# dp_sink_model: IP-XACT component
VLNV IcronTechnologies:IcronTechnologies:dp_sink_model:1.0

## Parameters
addr_width = 9
bus_width = 32

## Bus interfaces (logical=physical port)
default_map: slave AGNISYS:AGNISYS:APB:1.0, memory map dp_sinkmap
  pclk=pclk, presetn=presetn, psel=psel, penable=penable, pwrite=pwrite, pprot=pprot, pstrb=pstrb, pwdata=pwdata, paddr=paddr, pready=pready, prdata=prdata, pslverr=pslverr

## Ports
in pclk
in presetn
in psel
in penable
in pwrite
in pprot[2:0]
in pstrb[(bus_width div 8 )-1:0]
in pwdata[bus_width -1:0]
in paddr[addr_width -1:0]
out pready
out prdata[bus_width -1:0]
out pslverr
out dp_sink_regsversion_major_r[7:0]
out dp_sink_regsversion_minor_r[7:0]
out dp_sink_regsversion_patch_r[7:0]
out dp_sink_regsconfiguration_enb
out dp_sink_regsconfiguration_debug_msa_en_r
in dp_sink_regsconfiguration_tu_measured_in
in dp_sink_regsconfiguration_tu_measured_in_enb
in dp_sink_regsconfiguration_tico_ctrl_rst_in
in dp_sink_regsconfiguration_tico_ctrl_rst_in_enb
in dp_sink_regsconfiguration_vid_color_format_in[1:0]
in dp_sink_regsconfiguration_vid_color_format_in_enb
in dp_sink_regsconfiguration_vid_bit_per_component_in[2:0]
in dp_sink_regsconfiguration_vid_bit_per_component_in_enb
out dp_sink_regsconfiguration_vid_stream_extractor_en_r
out dp_sink_regsconfiguration_stream_extractor_en_r
out dp_sink_regsconfiguration_apb_to_axi_mode_select_r
out dp_sink_regsconfiguration_enh_frm_en_r
out dp_sink_regsconfiguration_lane_bit_rate_r[1:0]
out dp_sink_regsconfiguration_lane_num_r[1:0]
out dp_sink_regsdescrambler_enb
out dp_sink_regsdescrambler_enable_r
out dp_sink_regsaligner_control_enb
out dp_sink_regsaligner_control_tps3_n_tps2_r
out dp_sink_regsaligner_control_align_en_r
out dp_sink_regsaligner_stats_enb
out dp_sink_regsaligner_stats_lanes_not_aligned_cnt_rst_r
out dp_sink_regsaligner_stats_lanes_align_det_en_r
out dp_sink_regsstats_cnt_en_rst_8b10b_0_enb
out dp_sink_regsstats_cnt_en_rst_8b10b_0_lane{n}_8b10b_dis_err_post_cr_cnt_rst_r (n=0..3)
out dp_sink_regsstats_cnt_en_rst_8b10b_0_lanes_8b10b_dis_err_det_en_r
out dp_sink_regsstats_cnt_en_rst_8b10b_1_enb
out dp_sink_regsstats_cnt_en_rst_8b10b_1_lane{n}_8b10b_nit_err_post_cr_cnt_rst_r (n=0..3)
out dp_sink_regsstats_cnt_en_rst_8b10b_1_lanes_8b10b_nit_err_det_en_r
out dp_sink_regsstats_cnt_en_rst_gtp_enb
out dp_sink_regsstats_cnt_en_rst_gtp_dp_gt_rxbyterealign_cnt_rst_r
out dp_sink_regsstats_cnt_en_rst_gtp_dp_gt_rxbyterealign_cnt_en_r
out dp_sink_regsstream_extractor_cfg_enb
out dp_sink_regsstream_extractor_cfg_sdp_en_r
out dp_sink_regsstream_extractor_cfg_drop_sdp_ptp_pkt_r
out dp_sink_regsstream_extractor_cfg_drop_cs_ptp_pkt_r
out dp_sink_regsstream_extractor_cfg_cs_pkt_length_r[11:0]
out dp_sink_regsstream_extractor_alu_enb
out dp_sink_regsstream_extractor_alu_encoder_program_done_r
out dp_sink_regsstream_extractor_pixgen_enb
out dp_sink_regsstream_extractor_pixgen_en_r
out dp_sink_regsstream_extractor_pixgen_blue_r[7:0]
out dp_sink_regsstream_extractor_pixgen_green_r[7:0]
out dp_sink_regsstream_extractor_pixgen_red_r[7:0]
out dp_sink_regsstream_extractor_debug_enb
out dp_sink_regsstream_extractor_debug_idle_pattern_cnt_rst_r
out dp_sink_regsstream_extractor_msa_fps_enb
out dp_sink_regsstream_extractor_msa_fps_count_en_r
out dp_sink_regsstream_extractor_debug_msa_mvid_enb
out dp_sink_regsstream_extractor_debug_msa_mvid_mvid_r[23:0]
out dp_sink_regsstream_extractor_debug_msa_nvid_enb
out dp_sink_regsstream_extractor_debug_msa_nvid_nvid_r[23:0]
out dp_sink_regsstream_extractor_debug_msa_horizontal_0_enb
out dp_sink_regsstream_extractor_debug_msa_horizontal_0_total_r[15:0]
out dp_sink_regsstream_extractor_debug_msa_horizontal_0_start_r[15:0]
out dp_sink_regsstream_extractor_debug_msa_horizontal_1_enb
out dp_sink_regsstream_extractor_debug_msa_horizontal_1_width_r[15:0]
out dp_sink_regsstream_extractor_debug_msa_horizontal_1_polarity_r
out dp_sink_regsstream_extractor_debug_msa_horizontal_1_sync_width_r[14:0]
out dp_sink_regsstream_extractor_debug_msa_vertical_0_enb
out dp_sink_regsstream_extractor_debug_msa_vertical_0_total_r[15:0]
out dp_sink_regsstream_extractor_debug_msa_vertical_0_start_r[15:0]
out dp_sink_regsstream_extractor_debug_msa_vertical_1_enb
out dp_sink_regsstream_extractor_debug_msa_vertical_1_height_r[15:0]
out dp_sink_regsstream_extractor_debug_msa_vertical_1_polarity_r
out dp_sink_regsstream_extractor_debug_msa_vertical_1_sync_width_r[14:0]
out dp_sink_regsstream_extractor_debug_msa_misc_enb
out dp_sink_regsstream_extractor_debug_msa_misc_y_only_r
out dp_sink_regsstream_extractor_debug_msa_misc_stereo_r[1:0]
out dp_sink_regsstream_extractor_debug_msa_misc_int_total_r
out dp_sink_regsstream_extractor_debug_msa_misc_color_r[6:0]
out dp_sink_regsstream_extractor_debug_msa_misc_clk_sync_r
out dp_sink_regsstats0_rd2clr_config_rd_valid_out
out dp_sink_regsstats0_rd2clr_config_wr_valid_out
out dp_sink_regsstats0_vid_c{n}_fifo_full_rd_valid_out (n=0..2)
out dp_sink_regsstats0_vid_c{n}_fifo_empty_rd_valid_out (n=0..2)
out dp_sink_regsstats0_vid_c{n}_fifo_overflow_rd_valid_out (n=0..2)
out dp_sink_regsstats0_vid_c{n}_fifo_underflow_rd_valid_out (n=0..2)
out dp_sink_regsstats0_vid_c{n}_fifo_level_rd_valid_out (n=0..2)
out dp_sink_regsstats0_vid_c{n}_fifo_level_watermark_rd_valid_out (n=0..2)
out dp_sink_regsstats0_vid_c{n}_sr_full_rd_valid_out (n=0..2)
out dp_sink_regsstats0_vbd_majority_fail_rd_valid_out
out dp_sink_regsstats0_msa_majority_fail_rd_valid_out
out dp_sink_regsstats1_rd2clr_config_rd_valid_out
out dp_sink_regsstats1_rd2clr_config_wr_valid_out
out dp_sink_regsstats1_sdp_pkt_sent_cnt_rd_valid_out
out dp_sink_regsstats1_sdp_pkt_sent_cnt_watermark_rd_valid_out
out dp_sink_regsstats1_sdp_ss_se_same_cycle_rd_valid_out
out dp_sink_regsstats1_sdp_fifo_full_rd_valid_out
out dp_sink_regsstats1_sdp_fifo_empty_rd_valid_out
out dp_sink_regsstats1_sdp_fifo_overflow_rd_valid_out
out dp_sink_regsstats1_sdp_fifo_underflow_rd_valid_out
out dp_sink_regsstats1_sdp_fifo_level_rd_valid_out
out dp_sink_regsstats1_sdp_fifo_level_watermark_rd_valid_out
out dp_sink_regsstats1_sdp_tag_fifo_full_rd_valid_out
out dp_sink_regsstats1_sdp_tag_fifo_empty_rd_valid_out
out dp_sink_regsstats1_sdp_tag_fifo_overflow_rd_valid_out
out dp_sink_regsstats1_sdp_tag_fifo_underflow_rd_valid_out
out dp_sink_regsstats1_sdp_tag_fifo_level_rd_valid_out
out dp_sink_regsstats1_sdp_tag_fifo_level_watermark_rd_valid_out

## Address spaces and blocks
dp_sinkmap.dp_sink: base 0x000, range 0x200, width 32

## Registers
Registers are 32-bit, read-only, reset 0x0 unless marked. A register's access mark holds for its fields unless they carry their own. Offsets are from the block's base; lines under a group give offsets from that group; [hi:lo] are bit positions; {n}, {i} and the like mark numbered series; 'fields as' and 'values as' point back to an identical list; <NAME> marks a mode.

## dp_sinkmap.dp_sink — DP Sink
Base 0x00000000
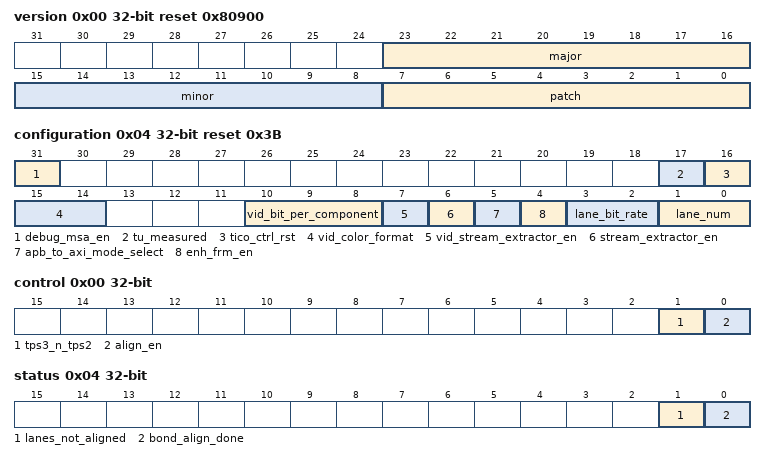
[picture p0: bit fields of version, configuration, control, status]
0x00 version reset 0x80900
  [23:16] major — Major version
  [15:8] minor — Minor version
  [7:0] patch — Patch version
0x04 configuration access per field reset 0x3B — General configuration
  [31] debug_msa_en rw — Enable debug MSA registers
  [17] tu_measured ro — tu_measured signal status
  [16] tico_ctrl_rst ro — Tico Encoder ctrl_rst pin status
  [15:14] vid_color_format ro — DP video color format 2'b00: RGB888 2'b01: YCbCr444 2'b10: YCbCr422 2'b11: YCbCr420
  [10:8] vid_bit_per_component ro — DP video bits per component 3'b000: 6 3'b001: 8 3'b010: 10 3'b011: 12 3'b100: 16
  [7] vid_stream_extractor_en rw — Enable video related stream_extractor module
  [6] stream_extractor_en rw — Enable stream_extractor module
  [5] apb_to_axi_mode_select rw — APB to AXI read mode select 1'b1: The read cycle is at least one clock later than read address cycle 1'b0: The read cycle happens at the same cycle as read address cycle
  [4] enh_frm_en rw — DP enhanced framing mode enable. The enhanced mode is enabled when this bit is set to 1.
  [3:2] lane_bit_rate rw — DP serial bit rate 2'b00: RBR (1.62 Gbps) 2'b01: HBR (2.70 Gbps) 2'b10: HBR2 (5.40 Gbps) 2'b11: HBR3(8.10 Gbps)
  [1:0] lane_num rw — Number of active dp lanes 2'b00: 1 lane 2'b01: 2 lanes 2'b10: Invalid 2'b11: 4 lanes
0x08 aligner group — Aligner module registers
  0x00 control rw — Aligner module control register
    [1] tps3_n_tps2 — Test pattern selection 1'b0: TPS2 1'b1: TPS3
    [0] align_en — Align module enable 1'b0: Disable 1'b1: Enable
  0x04 status — Aligner module bond/align status register
    [1] lanes_not_aligned — Alignment is not correct even though bond_align_done is set to high
    [0] bond_align_done — Alignment and bonding status. A "1" indicates all active lanes are bonded and aligned
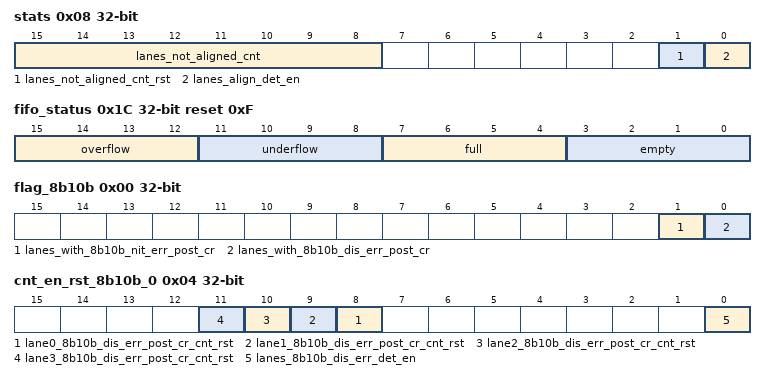
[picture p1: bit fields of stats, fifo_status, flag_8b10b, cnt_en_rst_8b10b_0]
  0x08 stats access per field — Aligner lanes not aligned
    [15:8] lanes_not_aligned_cnt ro — Number of clock cycles where lanes are not aligned after detection is enabled
    [1] lanes_not_aligned_cnt_rst rw — Align detector logic enable 1'b0: Disable 1'b1: Enable
    [0] lanes_align_det_en rw — Align detector logic enable 1'b0: Disable 1'b1: Enable
  0x0C debug group — Aligner debug stats
    0x00 stats1 — Aligner FSM
      [31:0] state_dbg
    0x04 stats2 — Aligner FIFO read enables
      [31:0] fifo_rd_en_dbg
    0x08 stats3 — Aligner comma detect
      [31:0] com_det_dbg
    0x0C stats4 — Aligner debug data
      [23:0] bond_align_debug_stats — Several stats for debugging
  0x1C fifo_status reset 0xF — Aligner module FIFO status register
    [15:12] overflow — FIFO overflow status. A "1" indicates overflow in FIFO. Bit[12] corresponds to lane 0 FIFO Bit[13] corresponds to lane 1 FIFO Bit[14] corresponds to lane 2 FIFO Bit[15] corresponds to lane 3 FIFO
    [11:8] underflow — FIFO underflow status. A "1" indicates underflow in FIFO. Bit[8] corresponds to lane 0 FIFO Bit[9] corresponds to lane 1 FIFO Bit[10] corresponds to lane 2 FIFO Bit[11] corresponds to lane 3 FIFO
    [7:4] full — FIFO full status. A "1" indicates FIFO is full Bit[4] corresponds to lane 0 FIFO Bit[5] corresponds to lane 1 FIFO Bit[6] corresponds to lane 2 FIFO Bit[7] corresponds to lane 3 FIFO
    [3:0] empty — FIFO empty status. A "1" indicates FIFO is empty Bit[0] corresponds to lane 0 FIFO Bit[1] corresponds to lane 1 FIFO Bit[2] corresponds to lane 2 FIFO Bit[3] corresponds to lane 3 FIFO
  0x20 fifo_config — Aligner depth
    [7:0] depth — FIFO depth. This value is used for the build
0x2C stats group — 8b10b and gtp debug stats
  0x00 flag_8b10b — 8b10b error flag
    [1] lanes_with_8b10b_nit_err_post_cr — There are 8b10b not in table decoder errors
    [0] lanes_with_8b10b_dis_err_post_cr — There are 8b10b disparity decoder errors
  0x04 cnt_en_rst_8b10b_0 rw — 8b10b disparity error counts reset
    [n+8] lane{n}_8b10b_dis_err_post_cr_cnt_rst (n=0..3) — 8b10b disparity error reset on lane {n}
    [0] lanes_8b10b_dis_err_det_en — 8b10b disparity error detector enable
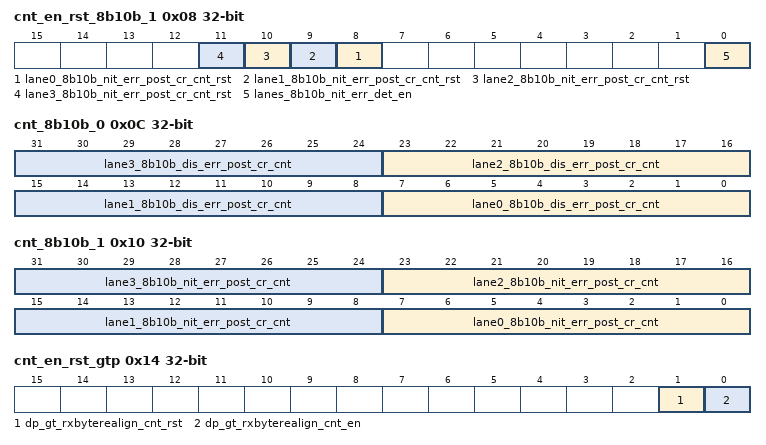
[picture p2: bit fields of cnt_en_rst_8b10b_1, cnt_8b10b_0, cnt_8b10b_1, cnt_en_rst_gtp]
  0x08 cnt_en_rst_8b10b_1 rw — 8b10b not in table error counts reset
    [n+8] lane{n}_8b10b_nit_err_post_cr_cnt_rst (n=0..3) — 8b10b not in table error reset on lane {n}
    [0] lanes_8b10b_nit_err_det_en — 8b10b not in table error detector enable
  0x0C cnt_8b10b_0 — 8b10b disparity error counts
    [8n+7:8n] lane{n}_8b10b_dis_err_post_cr_cnt (n=0..3) — Number of 8b10b disparity errors on lane {n}
  0x10 cnt_8b10b_1 — 8b10b not in table error counts
    [8n+7:8n] lane{n}_8b10b_nit_err_post_cr_cnt (n=0..3) — Number of 8b10b not in table errors on lane {n}
  0x14 cnt_en_rst_gtp rw — GTP realign counts
    [1] dp_gt_rxbyterealign_cnt_rst — Reset the rxbytealign counters
    [0] dp_gt_rxbyterealign_cnt_en — Enable the rxbyterealign counters
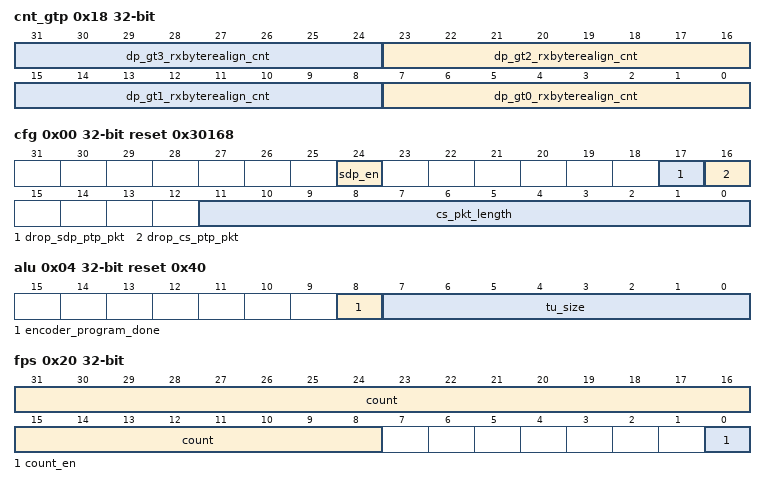
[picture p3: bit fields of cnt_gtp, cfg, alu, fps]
  0x18 cnt_gtp — GTP realign counts
    [8n+7:8n] dp_gt{n}_rxbyterealign_cnt (n=0..3) — Number of clock cycles where gt{n} symbol is realigned
0x48 descrambler rw
  [0] enable — Descrambler enable bit. The descrambler is enabled when this bit is set to 1. It is bypassed when this bit is set to 0.
0x4C stream_extractor group
  0x00 cfg rw reset 0x30168
    [24] sdp_en — Enable SDP
    [17] drop_sdp_ptp_pkt — Drop SDP packets going to MCA
    [16] drop_cs_ptp_pkt — Drop CS packets going to MCA
    [11:0] cs_pkt_length — Compressed video packet length
  0x04 alu access per field reset 0x40
    [8] encoder_program_done rw — Encoder programming is completed
    [7:0] tu_size ro — TU size receved from host
  0x08 msa group
    0x00 mvid
      [23:0] mvid — msa mvid value
    0x04 nvid
      [23:0] nvid — msa nvid value
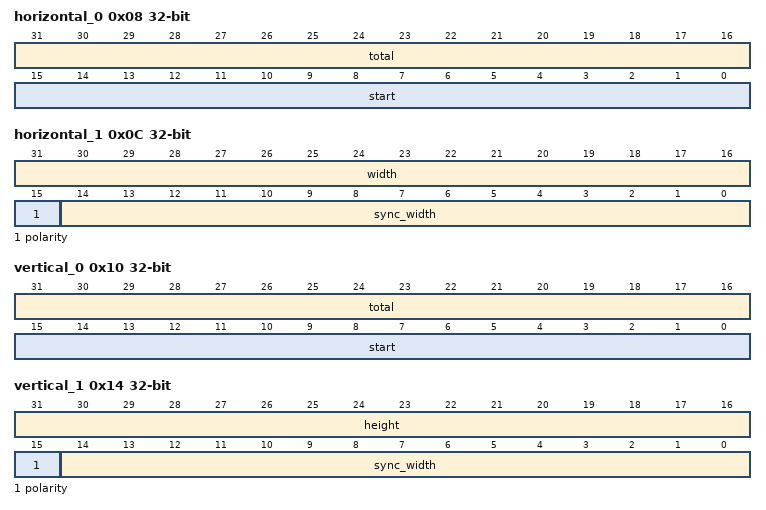
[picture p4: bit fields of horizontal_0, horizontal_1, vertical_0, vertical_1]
    0x08 horizontal_0
      [31:16] total — msa h total
      [15:0] start — msa h start
    0x0C horizontal_1
      [31:16] width — msa h width
      [15] polarity — msa h sync polarity (hsp)
      [14:0] sync_width — msa h sync width (hsw)
    0x10 vertical_0
      [31:16] total — msa v total
      [15:0] start — msa v start
    0x14 vertical_1
      [31:16] height — msa v height
      [15] polarity — msa v sync polarity (vsp)
      [14:0] sync_width — msa v sync width (vsw)
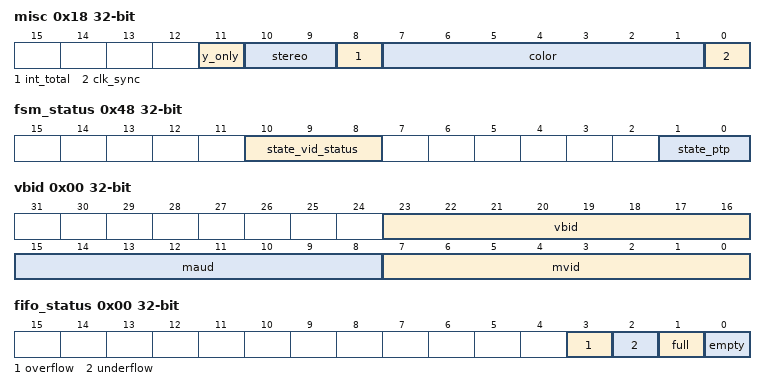
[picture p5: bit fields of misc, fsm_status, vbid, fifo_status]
    0x18 misc
      [11] y_only — msa misc_1 bit 7 field for Y-only video
      [10:9] stereo — msa misc_1 bits 2:1 field for Stereo video attribute 0 = No 3D video
      [8] int_total — msa misc_1 bit 0 field for interlaced video
      [7:1] color — msa misc_0 bits 7:1 for the Colorimetry field See DP 1.2 page 78 0x00 = RGB 18bpp 0x10 = RGB 24bpp 0x20 = RGB 30bpp 0x30 = RGB 36bpp 0x40 = RGB 48bpp
      [0] clk_sync — msa misc_0 bit 0 for synchronous clock. 0 = Link and main video clock are asynchronous 1 = Link and main video clock are synchronous
    0x1C status — Stream_extractor module status register
      [0] msa_majority_fail — MSA majority rule status. A "1" indicates that the majority rule failed
    0x20 fps access per field
      [31:8] count ro — Frame counter
      [0] count_en rw — Frame counter enable
  0x2C debug_msa group
    0x00 mvid rw
      [23:0] mvid — msa mvid value
    0x04 nvid rw
      [23:0] nvid — msa nvid value
    0x08 horizontal_0 rw reset 0xFA00036
      [31:16] total — msa h total
      [15:0] start — msa h start
    0x0C horizontal_1 rw reset 0xF000020
      fields as stream_extractor.msa.horizontal_1
    0x10 vertical_0 rw reset 0x8AE0050
      [31:16] total — msa v total
      [15:0] start — msa v start
    0x14 vertical_1 rw reset 0x8700005
      fields as stream_extractor.msa.vertical_1
    0x18 misc rw reset 0x20
      fields as stream_extractor.msa.misc
  0x48 fsm_status
    [10:8] state_vid_status — state_vid_status 3'b000: e_wait_sr 3'b001: e_wait_vb 3'b010: e_wait_be 3'b011: e_valid 3'b100: e_dummy
    [1:0] state_ptp — state_ptp 2'b00: e_ptp_idle 2'b01: e_ptp_header 2'b10: e_ptp_data 2'b11: e_ptp_footer
  0x4C vbd group
    0x00 vbid
      [23:16] vbid — vbid value
      [15:8] maud — maud value
      [7:0] mvid — Lower 8 bits of mvid[31:0]
    0x04 status — Stream_extractor module status register
      [0] vbd_majority_fail — VBID majority rule status. A "1" indicates that the majority rule failed
  0x54 vid_fifo_config
    [7:0] depth — FIFO depth. This value is used for the build
  0x58 sdp group
    0x00 fifo_status — SDP FIFO status register
      [3] overflow — FIFO overflow status. A "1" indicates overflow in FIFO.
      [2] underflow — FIFO underflow status. A "1" indicates underflow in FIFO.
      [1] full — FIFO full status. A "1" indicates FIFO is full
      [0] empty — FIFO empty status. A "1" indicates FIFO is empty
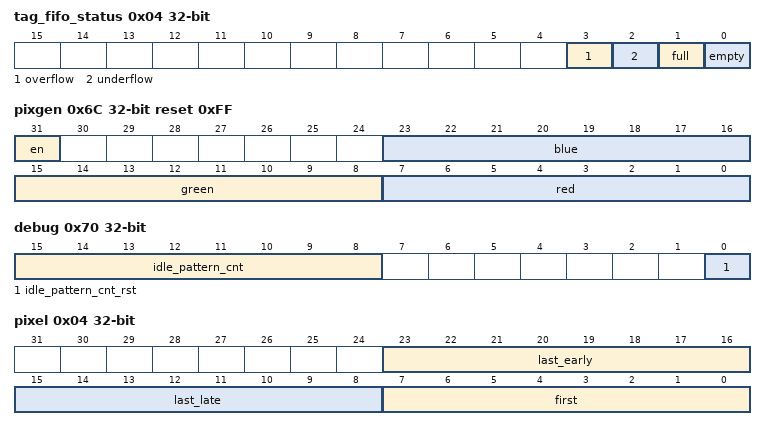
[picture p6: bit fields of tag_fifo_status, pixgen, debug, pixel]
    0x04 tag_fifo_status — SDP tag FIFO status register
      fields as stream_extractor.sdp.fifo_status
    0x08 fifo_config — SDP fifo depths
      [8:0] depth — FIFO depth. This value is used for the build
    0x0C tag_fifo_config — SDP fifo depths
      [6:0] depth — FIFO depth. This value is used for the build
    0x10 debug — SDP The SS and SE symbols' byte number
      [7:0] ss_se_same_cycle_byte_num — FIFO depth. This value is used for the build
  0x6C pixgen rw reset 0xFF — Pixel Generator
    [31] en — Pixel generator enable
    [23:16] blue — Pixel generator blue component
    [15:8] green — Pixel generator green component
    [7:0] red — Pixel generator red component
  0x70 debug access per field
    [15:8] idle_pattern_cnt ro — Idle pattern count
    [0] idle_pattern_cnt_rst rw — Idle pattern count reset
0xC0 encoder_vfr group
  0x00 handshake
    [7:0] handshake — Number of images with a fault on handshake (vid_enbl='1' while vid_ready='0')
  0x04 pixel
    [23:16] last_early — Number of images with pixel_last flag assert too early (line is too small)
    [15:8] last_late — Number of images with pixel_last flag assert too late (line is too long)
    [7:0] first — Number of images with pixel_first flag at the wrong position
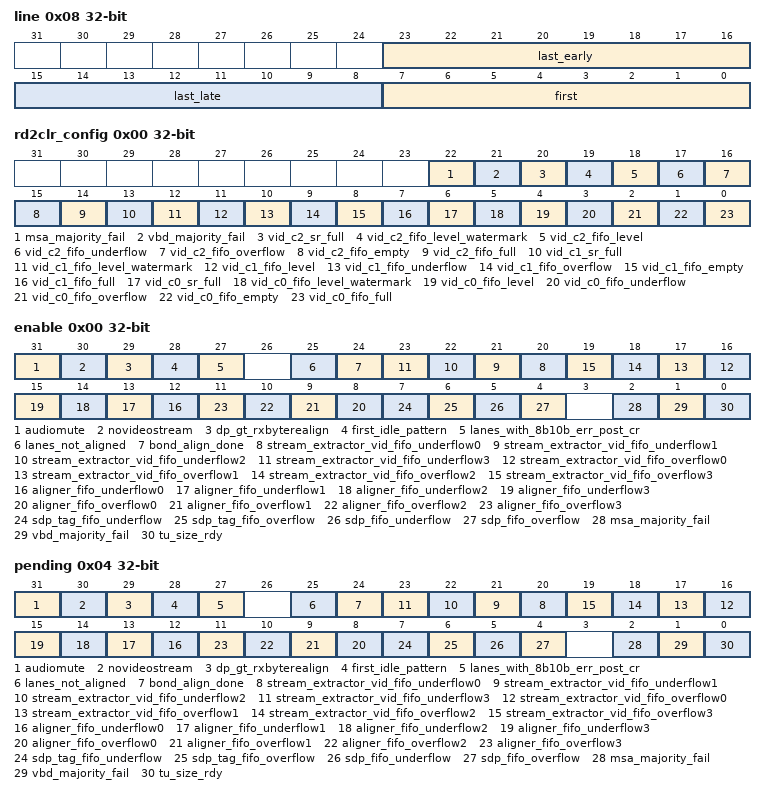
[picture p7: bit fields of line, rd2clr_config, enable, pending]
  0x08 line
    [23:16] last_early — Number of images with line_last flag assert too early (line is too small)
    [15:8] last_late — Number of images with line_last flag assert too late (line is too long)
    [7:0] first — Number of images with line_first flag at the wrong position
0xCC stats0 group — All the Statistic Registers and their configuration.
  0x00 rd2clr_config rw — Configures if the stats register read by s/w clears the read register. A 1 in any bit configures the h/w to clear the corresponding stats register after a s/w read of that stats register.
    [22] msa_majority_fail, [21] vbd_majority_fail, [20] vid_c2_sr_full, [19] vid_c2_fifo_level_watermark, [18] vid_c2_fifo_level, [17] vid_c2_fifo_underflow, [16] vid_c2_fifo_overflow, [15] vid_c2_fifo_empty, [14] vid_c2_fifo_full, [13] vid_c1_sr_full, [12] vid_c1_fifo_level_watermark, [11] vid_c1_fifo_level, [10] vid_c1_fifo_underflow, [9] vid_c1_fifo_overflow, [8] vid_c1_fifo_empty, [7] vid_c1_fifo_full, [6] vid_c0_sr_full, [5] vid_c0_fifo_level_watermark, [4] vid_c0_fifo_level, [3] vid_c0_fifo_underflow, [2] vid_c0_fifo_overflow, [1] vid_c0_fifo_empty, [0] vid_c0_fifo_full
  {0x4+0x1C*j} vid_c{j}_fifo_full (j=0..2) — Pixel C{j} FIFO full count
    [7:0] vid_c{j}_fifo_full — _icron_event_detect_rising_edge_
  {0x8+0x1C*j} vid_c{j}_fifo_empty (j=0..2) — Pixel C{j} FIFO empty count
    [7:0] vid_c{j}_fifo_empty — _icron_event_detect_rising_edge_
  {0xC+0x1C*j} vid_c{j}_fifo_overflow (j=0..2) — Pixel C{j} FIFO overflow count
    [7:0] vid_c{j}_fifo_overflow
  {0x10+0x1C*j} vid_c{j}_fifo_underflow (j=0..2) — Pixel C{j} FIFO underflow count
    [7:0] vid_c{j}_fifo_underflow
  {0x14+0x1C*j} vid_c{j}_fifo_level (j=0..2) — Pixel C{j} FIFO level
    [7:0] vid_c{j}_fifo_level — _icron_no_counter_
  {0x18+0x1C*j} vid_c{j}_fifo_level_watermark (j=0..2) — Pixel C{j} FIFO level Watermark
    [7:0] vid_c{j}_fifo_level_watermark — _icron_no_counter_;_icron_water_marker_
  {0x1C+0x1C*j} vid_c{j}_sr_full (j=0..2) — Pixel C{j} SR full
    [7:0] vid_c{j}_sr_full — _icron_event_detect_rising_edge_
  0x58 vbd_majority_fail — VBD majority fail count
    [7:0] vbd_majority_fail — _icron_event_detect_rising_edge_
  0x5C msa_majority_fail — MSA majority fail count
    [7:0] msa_majority_fail — _icron_event_detect_rising_edge_
0x12C stats1 group — All the Statistic Registers and their configuration.
  0x00 rd2clr_config rw — Configures if the stats register read by s/w clears the read register. A 1 in any bit configures the h/w to clear the corresponding stats register after a s/w read of that stats register.
    [14] sdp_tag_fifo_level_watermark, [13] sdp_tag_fifo_level, [12] sdp_tag_fifo_underflow, [11] sdp_tag_fifo_overflow, [10] sdp_tag_fifo_empty, [9] sdp_tag_fifo_full, [8] sdp_fifo_level_watermark, [7] sdp_fifo_level, [6] sdp_fifo_underflow, [5] sdp_fifo_overflow, [4] sdp_fifo_empty, [3] sdp_fifo_full, [2] sdp_ss_se_same_cycle, [1] sdp_pkt_sent_cnt_watermark, [0] sdp_pkt_sent_cnt
  0x04 sdp_pkt_sent_cnt — SDP Number of PTP packets sent
    [7:0] sdp_pkt_sent_cnt — _icron_no_counter_
  0x08 sdp_pkt_sent_cnt_watermark — SDP Number of packets sent watermark
    [7:0] sdp_pkt_sent_cnt_watermark — _icron_no_counter_;_icron_water_marker_
  0x0C sdp_ss_se_same_cycle — SDP number of clock cycles with ss and se
    [7:0] sdp_ss_se_same_cycle
  0x10 sdp_fifo_full — SDP FIFO full count
    [7:0] sdp_fifo_full — _icron_event_detect_rising_edge_
  0x14 sdp_fifo_empty — SDP FIFO empty count
    [7:0] sdp_fifo_empty — _icron_event_detect_rising_edge_
  0x18 sdp_fifo_overflow — SDP FIFO overflow count
    [7:0] sdp_fifo_overflow
  0x1C sdp_fifo_underflow — SDP FIFO underflow count
    [7:0] sdp_fifo_underflow
  0x20 sdp_fifo_level
    [15:0] sdp_fifo_level — _icron_no_counter_
  0x24 sdp_fifo_level_watermark
    [15:0] sdp_fifo_level_watermark — _icron_no_counter_;_icron_water_marker_
  0x28 sdp_tag_fifo_full — SDP TAG FIFO full count
    [7:0] sdp_tag_fifo_full — _icron_event_detect_rising_edge_
  0x2C sdp_tag_fifo_empty — SDP TAG FIFO empty count
    [7:0] sdp_tag_fifo_empty — _icron_event_detect_rising_edge_
  0x30 sdp_tag_fifo_overflow — SDP TAG FIFO overflow count
    [7:0] sdp_tag_fifo_overflow
  0x34 sdp_tag_fifo_underflow — SDP TAG FIFO underflow count
    [7:0] sdp_tag_fifo_underflow
  0x38 sdp_tag_fifo_level
    [7:0] sdp_tag_fifo_level — _icron_no_counter_
  0x3C sdp_tag_fifo_level_watermark
    [7:0] sdp_tag_fifo_level_watermark — _icron_no_counter_;_icron_water_marker_
0x16C irq group — source Interrupt register group
  0x00 enable rw — Interrupt Enable register - Write 1 to enable, 0 to mask an interrupt
    [31] audiomute — Set high to enable AudioMute_Flag
    [30] novideostream — Set high to enable NoVideoStream_Flag
    [29] dp_gt_rxbyterealign — Set high to enable dp_gt_rxbyterealign
    [28] first_idle_pattern — Set high to enable first_idle_pattern
    [27] lanes_with_8b10b_err_post_cr — Set high to enable lanes_with_8b10b_err_post_cr
    [25] lanes_not_aligned — Set high to enable lanes_not_aligned
    [24] bond_align_done — Set high to enable bond_align_done
    [n+20] stream_extractor_vid_fifo_underflow{n} (n=0..3) — Set high to enable stream_extractor_vid_fifo_underflow
    [n+16] stream_extractor_vid_fifo_overflow{n} (n=0..3) — Set high to enable stream_extractor_vid_fifo_overflow
    [n+12] aligner_fifo_underflow{n} (n=0..3) — Set high to enable aligner_fifo_underflow
    [n+8] aligner_fifo_overflow{n} (n=0..3) — Set high to enable aligner_fifo_overflow
    [7] sdp_tag_fifo_underflow — Set high to enable sdp_tag_fifo_underflow
    [6] sdp_tag_fifo_overflow — Set high to enable sdp_tag_fifo_overflow
    [5] sdp_fifo_underflow — Set high to enable sdp_fifo_underflow
    [4] sdp_fifo_overflow — Set high to enable sdp_fifo_overflow
    [2] msa_majority_fail — Set high to enable msa_majority_fail
    [1] vbd_majority_fail — Set high to enable vbd_majority_fail
    [0] tu_size_rdy — Set high to enable tu_size_rdy interrupt
  0x04 pending rw — Interrupt Pending register - This indicates which enabled interrupts have triggered, Write 1 to clear
    [31] audiomute write-1-clears — Registered AudioMute_Flag
    [30] novideostream write-1-clears — Registered NoVideoStream_Flag
    [29] dp_gt_rxbyterealign write-1-clears — Registered dp_gtp_rxbyterealign
    [28] first_idle_pattern write-1-clears — Registered first idle pattern
    [27] lanes_with_8b10b_err_post_cr write-1-clears — Registered lanes_with_8b10b_err_post_cr
    [25] lanes_not_aligned write-1-clears — Registered lanes_not_aligned
    [24] bond_align_done write-1-clears — Registered bond_align_done
    [n+20] stream_extractor_vid_fifo_underflow{n} write-1-clears (n=0..3) — Registered stream_extractor_vid_fifo_underflow
    [n+16] stream_extractor_vid_fifo_overflow{n} write-1-clears (n=0..3) — Registered stream_extractor_vid_fifo_overflow
    [n+12] aligner_fifo_underflow{n} write-1-clears (n=0..3) — Registered aligner_fifo_underflow
    [n+8] aligner_fifo_overflow{n} write-1-clears (n=0..3) — Registered aligner_fifo_overflow
    [7] sdp_tag_fifo_underflow write-1-clears — Registered sdp_tag_fifo_underflow
    [6] sdp_tag_fifo_overflow write-1-clears — Registered sdp_tag_fifo_overflow
    [5] sdp_fifo_underflow write-1-clears — Registered sdp_fifo_underflow
    [4] sdp_fifo_overflow write-1-clears — Registered sdp_fifo_overflow
    [2] msa_majority_fail write-1-clears — Registered msa_majority_fail
    [1] vbd_majority_fail write-1-clears — Registered vbd_majority_fail
    [0] tu_size_rdy write-1-clears — Registered tu_size_rdy 1: TU size value is ready to be read 0: TU is not ready or not applicable
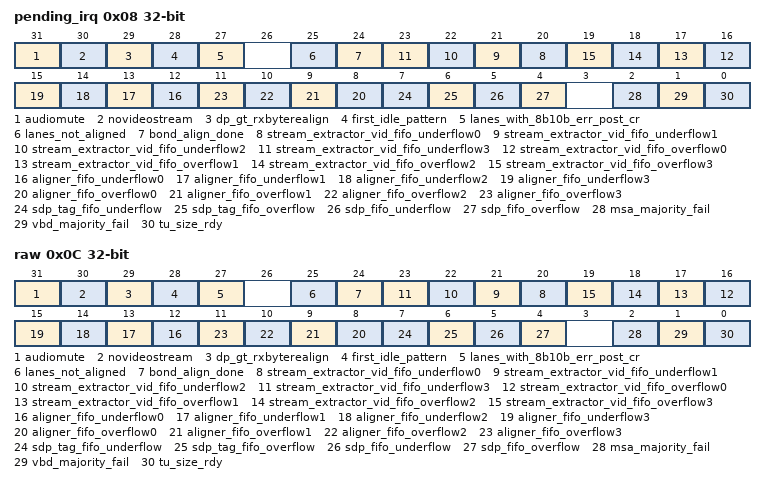
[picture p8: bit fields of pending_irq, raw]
  0x08 pending_irq — Interrupt Pending register - This indicates which enabled interrupts have triggered, Write 1 to clear
    [31] audiomute — Registered AudioMute_Flag
    [30] novideostream — Registered NoVideoStream_Flag
    [29] dp_gt_rxbyterealign — Registered dp_gtp_rxbyterealign
    [28] first_idle_pattern — Registered first idle pattern
    [27] lanes_with_8b10b_err_post_cr — Registered lanes_with_8b10b_err_post_cr
    [25] lanes_not_aligned — Registered lanes_not_aligned
    [24] bond_align_done — Registered bond_align_done
    [n+20] stream_extractor_vid_fifo_underflow{n} (n=0..3) — Registered stream_extractor_vid_fifo_underflow
    [n+16] stream_extractor_vid_fifo_overflow{n} (n=0..3) — Registered stream_extractor_vid_fifo_overflow
    [n+12] aligner_fifo_underflow{n} (n=0..3) — Registered aligner_fifo_underflow
    [n+8] aligner_fifo_overflow{n} (n=0..3) — Registered aligner_fifo_overflow
    [7] sdp_tag_fifo_underflow — Registered sdp_tag_fifo_underflow
    [6] sdp_tag_fifo_overflow — Registered sdp_tag_fifo_overflow
    [5] sdp_fifo_underflow — Registered sdp_fifo_underflow
    [4] sdp_fifo_overflow — Registered sdp_fifo_overflow
    [2] msa_majority_fail — Registered msa_majority_fail
    [1] vbd_majority_fail — Registered vbd_majority_fail
    [0] tu_size_rdy — Registered tu_size_rdy 1: TU size value is ready to be read 0: TU is not ready or not applicable
  0x0C raw — This register contains the registered state of interrupt signals
    [31] audiomute — Current status of AudioMute_Flag
    [30] novideostream — Current status of NoVideoStream_Flag
    [29] dp_gt_rxbyterealign — Current status of dp_gtp_rxbyterealign
    [28] first_idle_pattern — Current status of first_idle_pattern
    [27] lanes_with_8b10b_err_post_cr — Current status of lanes_with_8b10b_err_post_cr
    [25] lanes_not_aligned — Current status of lanes_not_aligned
    [24] bond_align_done — Current status of bond_align_done
    [n+20] stream_extractor_vid_fifo_underflow{n} (n=0..3) — Current status of stream_extractor_vid_fifo_underflow
    [n+16] stream_extractor_vid_fifo_overflow{n} (n=0..3) — Current status of stream_extractor_vid_fifo_overflow
    [n+12] aligner_fifo_underflow{n} (n=0..3) — Current status of aligner_fifo_underflow
    [n+8] aligner_fifo_overflow{n} (n=0..3) — Current status of aligner_fifo_overflow
    [7] sdp_tag_fifo_underflow — Current status of sdp_tag_fifo_underflow
    [6] sdp_tag_fifo_overflow — Current status of sdp_tag_fifo_overflow
    [5] sdp_fifo_underflow — Current status of sdp_fifo_underflow
    [4] sdp_fifo_overflow — Current status of sdp_fifo_overflow
    [2] msa_majority_fail — Current status of msa_majority_fail
    [1] vbd_majority_fail — Current status of vbd_majority_fail
    [0] tu_size_rdy — Current status of tu_size_rdy
